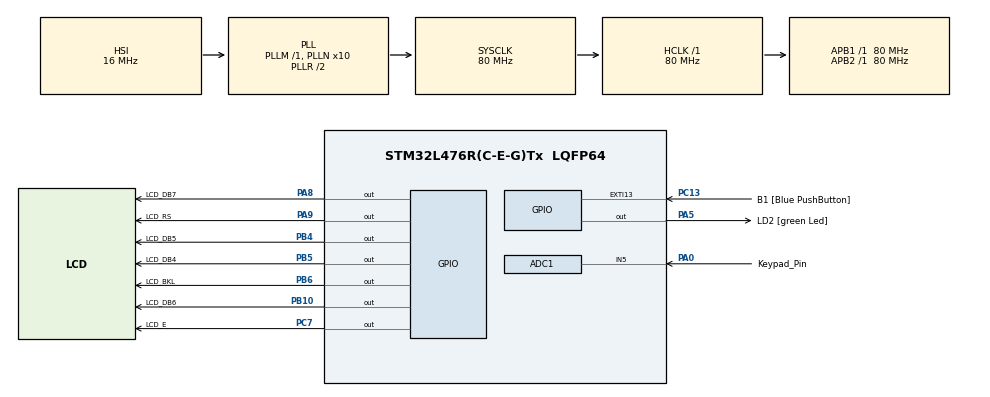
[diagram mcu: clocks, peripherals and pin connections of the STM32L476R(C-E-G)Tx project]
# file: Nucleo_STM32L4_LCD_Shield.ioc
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ADC1.Channel-0\#ChannelRegularConversion=ADC_CHANNEL_5
ADC1.NbrOfConversionFlag=1
ADC1.OffsetNumber-0\#ChannelRegularConversion=ADC_OFFSET_NONE
ADC1.Rank-0\#ChannelRegularConversion=1
ADC1.SamplingTime-0\#ChannelRegularConversion=ADC_SAMPLETIME_2CYCLES_5
ADC1.master=1
Mcu.Family=STM32L4
Mcu.Name=STM32L476R(C-E-G)Tx
Mcu.Package=LQFP64
NVIC.PriorityGroup=NVIC_PRIORITYGROUP_4
PA0.GPIO_Label=Keypad_Pin
PA0.Signal=ADCx_IN5
PA13.GPIO_Label=TMS
PA13.Signal=SYS_JTMS-SWDIO
PA14.GPIO_Label=TCK
PA14.Signal=SYS_JTCK-SWCLK
PA2.GPIO_Label=USART_TX
PA2.GPIO_Mode=GPIO_MODE_AF_PP
PA2.GPIO_PuPd=GPIO_NOPULL
PA2.GPIO_Speed=GPIO_SPEED_FREQ_VERY_HIGH
PA2.Signal=USART2_TX
PA3.GPIO_Label=USART_RX
PA3.GPIO_Mode=GPIO_MODE_AF_PP
PA3.GPIO_PuPd=GPIO_NOPULL
PA3.GPIO_Speed=GPIO_SPEED_FREQ_VERY_HIGH
PA3.Signal=USART2_RX
PA5.GPIO_Label=LD2 [green Led]
PA5.GPIO_ModeDefaultOutputPP=GPIO_MODE_OUTPUT_PP
PA5.GPIO_PuPd=GPIO_NOPULL
PA5.GPIO_Speed=GPIO_SPEED_FREQ_LOW
PA5.Signal=GPIO_Output
PA8.GPIO_Label=LCD_DB7
PA8.Signal=GPIO_Output
PA9.GPIO_Label=LCD_RS
PA9.Signal=GPIO_Output
PB10.GPIO_Label=LCD_DB6
PB10.Signal=GPIO_Output
PB3.GPIO_Label=SWO
PB3.Signal=SYS_JTDO-SWO
PB4.GPIO_Label=LCD_DB5
PB4.Signal=GPIO_Output
PB5.GPIO_Label=LCD_DB4
PB5.Signal=GPIO_Output
PB6.GPIO_Label=LCD_BKL
PB6.Signal=GPIO_Output
PC13.GPIO_Label=B1 [Blue PushButton]
PC13.GPIO_ModeDefaultEXTI=GPIO_MODE_EVT_RISING
PC13.GPIO_PuPd=GPIO_NOPULL
PC13.Signal=GPXTI13
PC14/OSC32_IN.Signal=RCC_OSC32_IN
PC15/OSC32_OUT.Signal=RCC_OSC32_OUT
PC7.GPIO_Label=LCD_E
PC7.Signal=GPIO_Output
PH0/OSC_IN.Signal=RCC_OSC_IN
PH1/OSC_OUT.Signal=RCC_OSC_OUT
ProjectManager.HeapSize=0x200
ProjectManager.StackSize=0x400
ProjectManager.TargetToolchain=SW4STM32
RCC.ADCFreq_Value=64000000
RCC.AHBFreq_Value=80000000
RCC.APB1Freq_Value=80000000
RCC.APB1TimFreq_Value=80000000
RCC.APB2Freq_Value=80000000
RCC.APB2TimFreq_Value=80000000
RCC.CortexFreq_Value=80000000
RCC.HCLKFreq_Value=80000000
RCC.HSE_VALUE=8000000
RCC.HSI_VALUE=16000000
RCC.LSE_VALUE=32768
RCC.MSI_VALUE=4000000
RCC.PLLN=10
RCC.PLLSourceVirtual=RCC_PLLSOURCE_HSI
RCC.PREFETCH_ENABLE=1
RCC.SYSCLKFreq_VALUE=80000000
RCC.SYSCLKSource=RCC_SYSCLKSOURCE_PLLCLK
RCC.USBFreq_Value=64000000
RCC.VCOOutputFreq_Value=160000000
SH.ADCx_IN5.0=ADC1_IN5,IN5-Single-Ended
board=NUCLEO-L476RG

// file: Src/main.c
/**
  ******************************************************************************
  * File Name          : main.c
  * Description        : Main program body
  ******************************************************************************
  *
  * COPYRIGHT(c) 2017 STMicroelectronics
  *
  * Redistribution and use in source and binary forms, with or without modification,
  * are permitted provided that the following conditions are met:
  *   1. Redistributions of source code must retain the above copyright notice,
  *      this list of conditions and the following disclaimer.
  *   2. Redistributions in binary form must reproduce the above copyright notice,
  *      this list of conditions and the following disclaimer in the documentation
  *      and/or other materials provided with the distribution.
  *   3. Neither the name of STMicroelectronics nor the names of its contributors
  *      may be used to endorse or promote products derived from this software
  *      without specific prior written permission.
  *
  * THIS SOFTWARE IS PROVIDED BY THE COPYRIGHT HOLDERS AND CONTRIBUTORS "AS IS"
  * AND ANY EXPRESS OR IMPLIED WARRANTIES, INCLUDING, BUT NOT LIMITED TO, THE
  * IMPLIED WARRANTIES OF MERCHANTABILITY AND FITNESS FOR A PARTICULAR PURPOSE ARE
  * DISCLAIMED. IN NO EVENT SHALL THE COPYRIGHT HOLDER OR CONTRIBUTORS BE LIABLE
  * FOR ANY DIRECT, INDIRECT, INCIDENTAL, SPECIAL, EXEMPLARY, OR CONSEQUENTIAL
  * DAMAGES (INCLUDING, BUT NOT LIMITED TO, PROCUREMENT OF SUBSTITUTE GOODS OR
  * SERVICES; LOSS OF USE, DATA, OR PROFITS; OR BUSINESS INTERRUPTION) HOWEVER
  * CAUSED AND ON ANY THEORY OF LIABILITY, WHETHER IN CONTRACT, STRICT LIABILITY,
  * OR TORT (INCLUDING NEGLIGENCE OR OTHERWISE) ARISING IN ANY WAY OUT OF THE USE
  * OF THIS SOFTWARE, EVEN IF ADVISED OF THE POSSIBILITY OF SUCH DAMAGE.
  *
  ******************************************************************************
  */
#include "main.h"
#include "stm32l4xx_hal.h"

/* USER CODE BEGIN Includes */
#include "hd44780.h"
#include "keypad.h"
/* USER CODE END Includes */

ADC_HandleTypeDef hadc1;

/* USER CODE BEGIN PV */
/* Private variables ---------------------------------------------------------*/

/* USER CODE END PV */

void SystemClock_Config(void);
void Error_Handler(void);
static void MX_GPIO_Init(void);
static void MX_ADC1_Init(void);

/* USER CODE BEGIN PFP */
/* Private function prototypes -----------------------------------------------*/

/* USER CODE END PFP */

int main(void)
{

  /* USER CODE BEGIN 1 */
	uint16_t key_val = 0;
	static const uint8_t* key_name[] = {"RIGHT", "UP", "DOWN", "LEFT", "SELECT", "NONE  "};
  /* USER CODE END 1 */

  /* MCU Configuration----------------------------------------------------------*/

  /* Reset of all peripherals, Initializes the Flash interface and the Systick. */
  HAL_Init();

  /* Configure the system clock */
  SystemClock_Config();

  /* Initialize all configured peripherals */
  MX_GPIO_Init();
  MX_ADC1_Init();

  /* USER CODE BEGIN 2 */
  keypad_init(&hadc1);
  char_lcd_init();
  char_lcd_write_string("PRESS KEY", 1, 0);
  char_lcd_write_string("PRESSED: ", 2, 0);
  HAL_GPIO_WritePin(GPIOB, LCD_BKL_Pin, GPIO_PIN_SET);

//  HAL_Delay(2000);
//  HAL_GPIO_WritePin(GPIOB, LCD_BKL_Pin, GPIO_PIN_RESET);

  /* USER CODE END 2 */

  /* Infinite loop */
  /* USER CODE BEGIN WHILE */
  while (1)
  {
	  key_val = keypad_read_key(&hadc1);
	  char_lcd_write_string(key_name[key_val], 2, 10);
	  HAL_Delay(100);
  /* USER CODE END WHILE */

  }

}

/** System Clock Configuration
*/
void SystemClock_Config(void)
{

  RCC_OscInitTypeDef RCC_OscInitStruct;
  RCC_ClkInitTypeDef RCC_ClkInitStruct;
  RCC_PeriphCLKInitTypeDef PeriphClkInit;

    /**Initializes the CPU, AHB and APB busses clocks
    */
  RCC_OscInitStruct.OscillatorType = RCC_OSCILLATORTYPE_HSI;
  RCC_OscInitStruct.HSIState = RCC_HSI_ON;
  RCC_OscInitStruct.HSICalibrationValue = 16;
  RCC_OscInitStruct.PLL.PLLState = RCC_PLL_ON;
  RCC_OscInitStruct.PLL.PLLSource = RCC_PLLSOURCE_HSI;
  RCC_OscInitStruct.PLL.PLLM = 1;
  RCC_OscInitStruct.PLL.PLLN = 10;
  RCC_OscInitStruct.PLL.PLLP = RCC_PLLP_DIV7;
  RCC_OscInitStruct.PLL.PLLQ = RCC_PLLQ_DIV2;
  RCC_OscInitStruct.PLL.PLLR = RCC_PLLR_DIV2;
  if (HAL_RCC_OscConfig(&RCC_OscInitStruct) != HAL_OK)
  {
    Error_Handler();
  }

    /**Initializes the CPU, AHB and APB busses clocks
    */
  RCC_ClkInitStruct.ClockType = RCC_CLOCKTYPE_HCLK|RCC_CLOCKTYPE_SYSCLK
                              |RCC_CLOCKTYPE_PCLK1|RCC_CLOCKTYPE_PCLK2;
  RCC_ClkInitStruct.SYSCLKSource = RCC_SYSCLKSOURCE_PLLCLK;
  RCC_ClkInitStruct.AHBCLKDivider = RCC_SYSCLK_DIV1;
  RCC_ClkInitStruct.APB1CLKDivider = RCC_HCLK_DIV1;
  RCC_ClkInitStruct.APB2CLKDivider = RCC_HCLK_DIV1;

  if (HAL_RCC_ClockConfig(&RCC_ClkInitStruct, FLASH_LATENCY_4) != HAL_OK)
  {
    Error_Handler();
  }

  PeriphClkInit.PeriphClockSelection = RCC_PERIPHCLK_ADC;
  PeriphClkInit.AdcClockSelection = RCC_ADCCLKSOURCE_PLLSAI1;
  PeriphClkInit.PLLSAI1.PLLSAI1Source = RCC_PLLSOURCE_HSI;
  PeriphClkInit.PLLSAI1.PLLSAI1M = 1;
  PeriphClkInit.PLLSAI1.PLLSAI1N = 8;
  PeriphClkInit.PLLSAI1.PLLSAI1P = RCC_PLLP_DIV7;
  PeriphClkInit.PLLSAI1.PLLSAI1Q = RCC_PLLQ_DIV2;
  PeriphClkInit.PLLSAI1.PLLSAI1R = RCC_PLLR_DIV2;
  PeriphClkInit.PLLSAI1.PLLSAI1ClockOut = RCC_PLLSAI1_ADC1CLK;
  if (HAL_RCCEx_PeriphCLKConfig(&PeriphClkInit) != HAL_OK)
  {
    Error_Handler();
  }

    /**Configure the main internal regulator output voltage
    */
  if (HAL_PWREx_ControlVoltageScaling(PWR_REGULATOR_VOLTAGE_SCALE1) != HAL_OK)
  {
    Error_Handler();
  }

    /**Configure the Systick interrupt time
    */
  HAL_SYSTICK_Config(HAL_RCC_GetHCLKFreq()/1000);

    /**Configure the Systick
    */
  HAL_SYSTICK_CLKSourceConfig(SYSTICK_CLKSOURCE_HCLK);

  /* SysTick_IRQn interrupt configuration */
  HAL_NVIC_SetPriority(SysTick_IRQn, 0, 0);
}

/* ADC1 init function */
static void MX_ADC1_Init(void)
{

  ADC_MultiModeTypeDef multimode;
  ADC_ChannelConfTypeDef sConfig;

    /**Common config
    */
  hadc1.Instance = ADC1;
  hadc1.Init.ClockPrescaler = ADC_CLOCK_ASYNC_DIV1;
  hadc1.Init.Resolution = ADC_RESOLUTION_12B;
  hadc1.Init.DataAlign = ADC_DATAALIGN_RIGHT;
  hadc1.Init.ScanConvMode = ADC_SCAN_DISABLE;
  hadc1.Init.EOCSelection = ADC_EOC_SINGLE_CONV;
  hadc1.Init.LowPowerAutoWait = DISABLE;
  hadc1.Init.ContinuousConvMode = DISABLE;
  hadc1.Init.NbrOfConversion = 1;
  hadc1.Init.DiscontinuousConvMode = DISABLE;
  hadc1.Init.NbrOfDiscConversion = 1;
  hadc1.Init.ExternalTrigConv = ADC_SOFTWARE_START;
  hadc1.Init.ExternalTrigConvEdge = ADC_EXTERNALTRIGCONVEDGE_NONE;
  hadc1.Init.DMAContinuousRequests = DISABLE;
  hadc1.Init.Overrun = ADC_OVR_DATA_PRESERVED;
  hadc1.Init.OversamplingMode = DISABLE;
  if (HAL_ADC_Init(&hadc1) != HAL_OK)
  {
    Error_Handler();
  }

    /**Configure the ADC multi-mode
    */
  multimode.Mode = ADC_MODE_INDEPENDENT;
  if (HAL_ADCEx_MultiModeConfigChannel(&hadc1, &multimode) != HAL_OK)
  {
    Error_Handler();
  }

    /**Configure Regular Channel
    */
  sConfig.Channel = ADC_CHANNEL_5;
  sConfig.Rank = 1;
  sConfig.SamplingTime = ADC_SAMPLETIME_2CYCLES_5;
  sConfig.SingleDiff = ADC_SINGLE_ENDED;
  sConfig.OffsetNumber = ADC_OFFSET_NONE;
  sConfig.Offset = 0;
  if (HAL_ADC_ConfigChannel(&hadc1, &sConfig) != HAL_OK)
  {
    Error_Handler();
  }

}

/** Configure pins as
        * Analog
        * Input
        * Output
        * EVENT_OUT
        * EXTI
     PA2   ------> USART2_TX
     PA3   ------> USART2_RX
*/
static void MX_GPIO_Init(void)
{

  GPIO_InitTypeDef GPIO_InitStruct;

  /* GPIO Ports Clock Enable */
  __HAL_RCC_GPIOC_CLK_ENABLE();
  __HAL_RCC_GPIOH_CLK_ENABLE();
  __HAL_RCC_GPIOA_CLK_ENABLE();
  __HAL_RCC_GPIOB_CLK_ENABLE();

  /*Configure GPIO pin Output Level */
  HAL_GPIO_WritePin(GPIOA, LD2_Pin|LCD_DB7_Pin|LCD_RS_Pin, GPIO_PIN_RESET);

  /*Configure GPIO pin Output Level */
  HAL_GPIO_WritePin(GPIOB, LCD_DB6_Pin|LCD_DB5_Pin|LCD_DB4_Pin|LCD_BKL_Pin, GPIO_PIN_RESET);

  /*Configure GPIO pin Output Level */
  HAL_GPIO_WritePin(LCD_E_GPIO_Port, LCD_E_Pin, GPIO_PIN_RESET);

  /*Configure GPIO pin : B1_Pin */
  GPIO_InitStruct.Pin = B1_Pin;
  GPIO_InitStruct.Mode = GPIO_MODE_EVT_RISING;
  GPIO_InitStruct.Pull = GPIO_NOPULL;
  HAL_GPIO_Init(B1_GPIO_Port, &GPIO_InitStruct);

  /*Configure GPIO pins : USART_TX_Pin USART_RX_Pin */
  GPIO_InitStruct.Pin = USART_TX_Pin|USART_RX_Pin;
  GPIO_InitStruct.Mode = GPIO_MODE_AF_PP;
  GPIO_InitStruct.Pull = GPIO_NOPULL;
  GPIO_InitStruct.Speed = GPIO_SPEED_FREQ_VERY_HIGH;
  GPIO_InitStruct.Alternate = GPIO_AF7_USART2;
  HAL_GPIO_Init(GPIOA, &GPIO_InitStruct);

  /*Configure GPIO pins : LD2_Pin LCD_DB7_Pin LCD_RS_Pin */
  GPIO_InitStruct.Pin = LD2_Pin|LCD_DB7_Pin|LCD_RS_Pin;
  GPIO_InitStruct.Mode = GPIO_MODE_OUTPUT_PP;
  GPIO_InitStruct.Pull = GPIO_NOPULL;
  GPIO_InitStruct.Speed = GPIO_SPEED_FREQ_LOW;
  HAL_GPIO_Init(GPIOA, &GPIO_InitStruct);

  /*Configure GPIO pins : LCD_DB6_Pin LCD_DB5_Pin LCD_DB4_Pin LCD_BKL_Pin */
  GPIO_InitStruct.Pin = LCD_DB6_Pin|LCD_DB5_Pin|LCD_DB4_Pin|LCD_BKL_Pin;
  GPIO_InitStruct.Mode = GPIO_MODE_OUTPUT_PP;
  GPIO_InitStruct.Pull = GPIO_NOPULL;
  GPIO_InitStruct.Speed = GPIO_SPEED_FREQ_LOW;
  HAL_GPIO_Init(GPIOB, &GPIO_InitStruct);

  /*Configure GPIO pin : LCD_E_Pin */
  GPIO_InitStruct.Pin = LCD_E_Pin;
  GPIO_InitStruct.Mode = GPIO_MODE_OUTPUT_PP;
  GPIO_InitStruct.Pull = GPIO_NOPULL;
  GPIO_InitStruct.Speed = GPIO_SPEED_FREQ_LOW;
  HAL_GPIO_Init(LCD_E_GPIO_Port, &GPIO_InitStruct);

}

void Error_Handler(void)
{
  while(1)
  {
  }
}

/************************ (C) COPYRIGHT STMicroelectronics *****END OF FILE****/
